# pass register map
Vendor: Texas Instruments
Peripheral module from a debugger description file (folder Keystone2).
Registers are 32-bit, read-write, no defined reset value unless marked. A register's access mark holds for its fields unless they carry their own. Offsets are as the file gives them; lines under a group give offsets from that group; [hi:lo] are bit positions; {n}, {i} and the like mark numbered series; 'fields as' and 'values as' point back to an identical list; <NAME> marks a mode.

## NETCP
0x00 MBOX_SLOT — (1 of 6, stride 16)
  [31:0] status_bits
0x00 PDSP_RAM — (1 of 2048, stride 4)
  [31:0] RAM — PDSP RAM
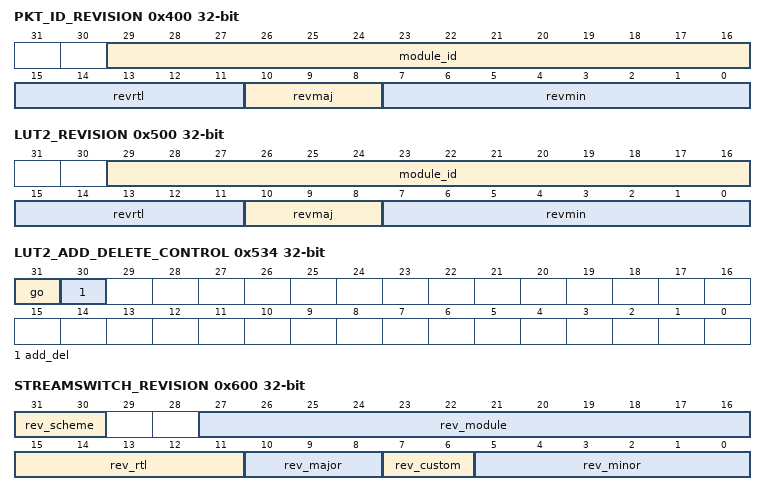
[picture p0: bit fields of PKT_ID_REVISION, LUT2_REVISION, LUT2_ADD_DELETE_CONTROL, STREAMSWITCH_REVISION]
0x400 PKT_ID_REVISION ro — (1 of 1, stride 0)
  [29:16] module_id
  [15:11] revrtl — RTL revision
  [10:8] revmaj — Major revision
  [7:0] revmin — Minor revision
0x404 PKT_ID_SOFT_RESET wo — (1 of 1, stride 0)
  [31:0] trigger — Writing anything to this field causes all internal statistics to be cleared
0x408 PKT_ID_RANGE_LIMIT — (1 of 1, stride 0)
  [9:0] range_limit — Contains the value of the highest allowable ID returned by allocation
0x40C PKT_ID_VALUE — (1 of 1, stride 0)
  [10:0] id_value — When read, returns the value of a newly allocated packet ID, or returns 0x400 when no packet ID is available. When written, frees the supplied packet ID.
0x500 LUT2_REVISION ro — (1 of 1, stride 0)
  fields as PKT_ID_REVISION
0x504 LUT2_SOFT_RESET wo — (1 of 1, stride 0)
  [31:0] trigger — Writing anything to this field causes the LUT to be cleared. This operation takes 2 clock cycles to complete.
0x520 LUT2_ADD_DATA_N — (1 of 1, stride 0)
  [31:0] data — This is the data which will be placed in bits ((32*N)+31):(32*N) of the data portion of the added table entry.
0x530 LUT2_ADD_DELETE_KEY — (1 of 1, stride 0)
  [31:0] key — This is the key which will be matched against during the search operation.
0x534 LUT2_ADD_DELETE_CONTROL — (1 of 1, stride 0)
  [31] go — Go bit. Writing this bit will cause the add / delete operation to start. Once started, the operation cannot be cancelled. This bit will remain asserted until the add or delete operation completes.
  [30] add_del — Add / delete control bit: 0=Delete entry, 1=Add entry
0x600 STREAMSWITCH_REVISION ro — (1 of 1, stride 0)
  [31:30] rev_scheme — Scheme
  [27:16] rev_module — Module ID
  [15:11] rev_rtl — RTL revisions
  [10:8] rev_major — Major revision
  [7:6] rev_custom — Custom revision
  [5:0] rev_minor — Minor revision
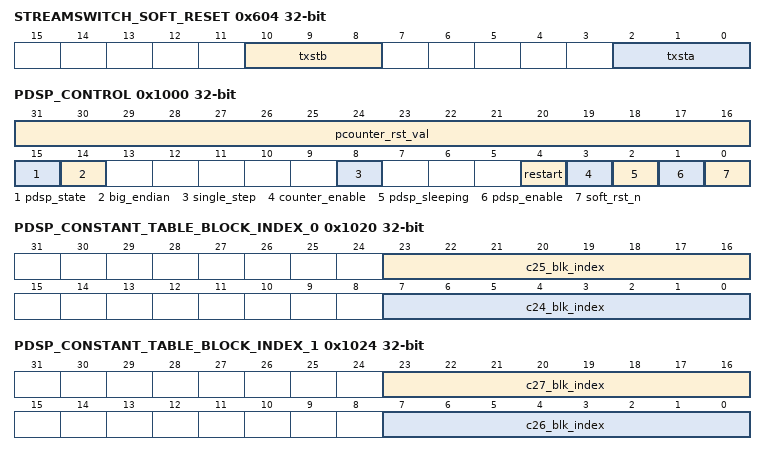
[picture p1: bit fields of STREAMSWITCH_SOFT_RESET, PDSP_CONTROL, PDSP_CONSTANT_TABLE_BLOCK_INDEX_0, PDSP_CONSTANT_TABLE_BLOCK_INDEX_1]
0x604 STREAMSWITCH_SOFT_RESET — (1 of 1, stride 0)
  [10:8] txstb — This field maps the CPSW txstb port to a physical slave thread.
  [2:0] txsta — This field maps the CPSW txsta port to a physical slave thread.
0x1000 PDSP_CONTROL access per field — (1 of 6, stride 256)
  [31:16] pcounter_rst_val rw — Program counter reset value
  [15] pdsp_state ro — PDSP run state: 0=PDSP is halted, 1=PDSP is running
  [14] big_endian ro — Big-endian input state
  [8] single_step rw — Single step enable: 0=PDSP will free run when enabled, 1=PDSP will execute a single instruction and then the pdsp_enable bit will be cleared
  [4] restart rw — Causes PDSP to stop current operation gracefully and return to the PC reset value
  [3] counter_enable rw — PDSP cycle counter enable: 0=Counters not enabled, 1=Counters enabled
  [2] pdsp_sleeping rw — PDSP sleep indicator: 0=PDSP is not asleep, 1=PDSP us asleep
  [1] pdsp_enable rw — PDSP enable: 0=PDSP is disabled, 1=PDSP is enabled
  [0] soft_rst_n ro — Soft reset. When this bit is cleared, the PDSP will be reset. This bit is set back to 1 on the next cycle after it has been cleared.
0x1004 PDSP_STATUS ro — (1 of 6, stride 256)
  [15:0] pcounter — Current PDSP program counter
0x1008 PDSP_WAKEUP_ENABLE — (1 of 6, stride 256)
  [31:0] bitwise_enables — Wakeup enables
0x100C PDSP_CYCLE_COUNT — (1 of 6, stride 256)
  [31:0] cyclecount — This value is incremented by 1 for every clock cycle during which the PDSP is enabled and the counter is enabled.
0x1010 PDSP_STALL_COUNT ro — (1 of 6, stride 256)
  [31:0] stallcount — This value is incremented by 1 for every clock cycle during which the PDSP is enabled, the counter is enabled, and the PDSP was unable to fetch a new instruction for any reason.
0x1020 PDSP_CONSTANT_TABLE_BLOCK_INDEX_0 — (1 of 6, stride 256)
  [23:16] c25_blk_index — PDSP constant entry 25 block index
  [7:0] c24_blk_index — PDSP constant entry 24 block index
0x1024 PDSP_CONSTANT_TABLE_BLOCK_INDEX_1 — (1 of 6, stride 256)
  [23:16] c27_blk_index — PDSP constant entry 27 block index
  [7:0] c26_blk_index — PDSP constant entry 26 block index
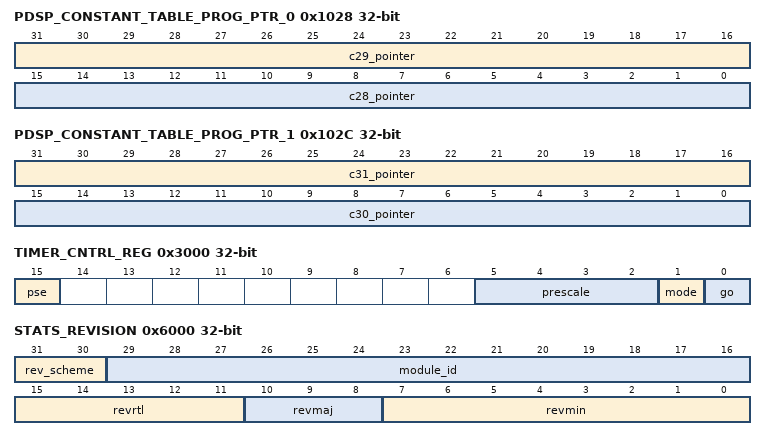
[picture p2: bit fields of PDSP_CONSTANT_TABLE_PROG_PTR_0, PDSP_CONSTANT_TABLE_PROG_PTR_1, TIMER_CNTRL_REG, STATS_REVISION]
0x1028 PDSP_CONSTANT_TABLE_PROG_PTR_0 — (1 of 6, stride 256)
  [31:16] c29_pointer — PDSP constant entry 29 pointer
  [15:0] c28_pointer — PDSP constant entry 28 pointer
0x102C PDSP_CONSTANT_TABLE_PROG_PTR_1 — (1 of 6, stride 256)
  [31:16] c31_pointer — PDSP constant entry 31 pointer
  [15:0] c30_pointer — PDSP constant entry 30 pointer
0x2000 PDSP_IGP — (1 of 6, stride 256)
  [31:0] regN — PDSP Internal GP Register N
0x2080 PDSP_ICTE ro — (1 of 6, stride 256)
  [31:0] ct_entryN — PDSP Internal Constants Table Entry N
0x3000 TIMER_CNTRL_REG — (1 of 6, stride 256)
  [15] pse — Pre-scale enable: 0=disabled, 1=enabled
  [5:2] prescale — Pre-scale value
  [1] mode — Timer count mode: 0=one-shot mode, 1=auto-load mode
  [0] go — Timer start/stop: 0=stop, 1=start
0x3004 TIMER_LOAD_REG wo — (1 of 6, stride 256)
  [15:0] count — Value to be counted down from
0x3008 TIMER_VALUE_REG ro — (1 of 6, stride 256)
  [15:0] curr_count — Current 16-bit count down value
0x300C TIMER_IRQ_REG — (1 of 6, stride 256)
  [0] interrupt — Timer interrupt status: 0=inactive, 1=active
0x6000 STATS_REVISION ro — (1 of 1, stride 0)
  [31:30] rev_scheme — Scheme
  [29:16] module_id
  [15:11] revrtl — RTL revision
  [10:8] revmaj — Major revision
  [7:0] revmin — Minor revision
0x6004 STATS_SOFT_RESET wo — (1 of 1, stride 0)
  [31:0] trigger — Writing anything to this field causes all internal statistics to be cleared.
0x6008 STATS_INC_FLAGS wo — (1 of 1, stride 0)
  [31:0] inc_flags — Each flag corresponds to a statistic to increment. Bit 0 corresponds to the Statistic 0 register. The amount to increment is 1.
0x600C STATS_CAPTURE wo — (1 of 1, stride 0)
  [31:0] stat_capture — Each flag corresponds to a statistic. Bit 0 corresponds to the Statistic 0 register. Writing any value to this register causes all 32 statistic values to be captured. For any bit that is set to 1, the corresponding statistic is also cleared after being
0x6020 STATS_COUNT_N ro — (1 of 1, stride 0)
  [31:0] stat_count — Holds the 32-bit value of the statistic.
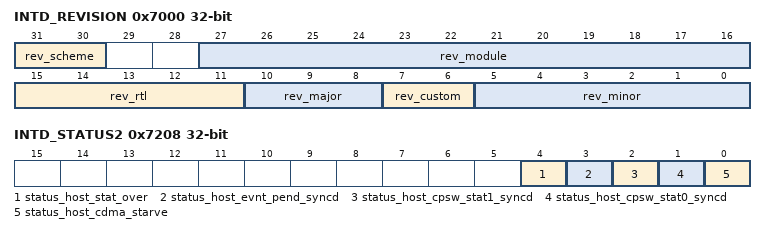
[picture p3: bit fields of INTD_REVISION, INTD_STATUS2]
0x7000 INTD_REVISION ro — (1 of 1, stride 0)
  fields as STREAMSWITCH_REVISION
0x7010 INTD_EOI — (1 of 1, stride 0)
  [7:0] eoi_vector — End of Interrupt Vector
0x7014 INTD_INTR_VECTOR ro — (1 of 1, stride 0)
  [31:0] intr_vector — Interrupt Vector Register
0x7200 INTD_STATUS0 — (1 of 1, stride 0)
  [31:0] status_host_in_intr — Status (write 1 to set) for in_intr
0x7204 INTD_STATUS1 ro — (1 of 1, stride 0)
  [31:0] status_host_lintr — Status for lintr
0x7208 INTD_STATUS2 access per field — (1 of 1, stride 0)
  [4] status_host_stat_over ro — Status for stat_over
  [3] status_host_evnt_pend_syncd ro — Status for evnt_pend
  [2] status_host_cpsw_stat1_syncd ro — Status for cpsw_stat1
  [1] status_host_cpsw_stat0_syncd ro — Status for cpsw_stat0
  [0] status_host_cdma_starve rw — Status (write 1 to set) for cdma_starve
0x7280 INTD_STATUS_CLR0 — (1 of 1, stride 0)
  [31:0] status_host_in_intr_clr — Status (write 1 to clear) for in_intr
0x7288 INTD_STATUS_CLR2 — (1 of 1, stride 0)
  [0] status_host_cdma_starve_clr — Status (write 1 to clear) for cdma_starve
0x7300 INTD_INTCNT ro — (1 of 1, stride 0)
  [7:0] intcnt_host_cnt_in_intr — Interrupt Count for host_cnt_in_intr (write to decrement)
0x7480 INTD_INTR_VECTOR_HOST ro — (1 of 1, stride 0)
  [31:0] intr_vector_host — Interrupt Vector
0x10000 PDSP_RAM — (1 of 6, stride 32768)
  [31:0] RAM — PDSP RAM
0x40000 PDSP_RAM — (1 of 4, stride 8192)
  [31:0] RAM — PDSP RAM
